# CCG2 register map
File version: 1.0
CPU: CM0 r1p0, little endian, no MPU, no FPU, 2 interrupt priority bits
Registers are 32-bit, read-write, reset 0x0 unless marked. A register's access mark holds for its fields unless they carry their own. Offsets are from the block's base; [hi:lo] are bit positions; lines under a group give offsets from that group; {n}, {i} and the like mark numbered series; 'fields as' and 'values as' point back to an identical list; <NAME> marks a mode.

## GPIO
Base 0x40040000
0x00 PRT0 group
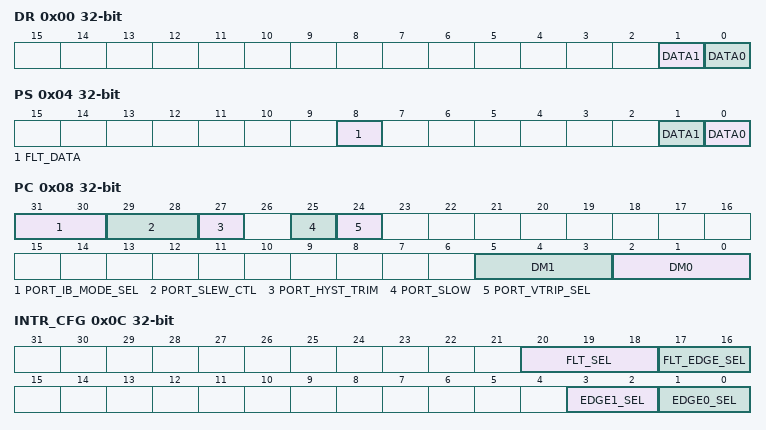
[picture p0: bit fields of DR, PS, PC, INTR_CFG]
  0x00 DR — Port output data register Used to read and write the output data for the IO pads in the port. A DR register write changes the output data to the written value. A DR register read reflects the output data (and not the current state of the input data for the IO pads). Using this DR register, Read-Modify-Write sequences are safely performed on a port with some IO pads configured as inputs.
    [1] DATA1 — IO pad 1 output data.
    [0] DATA0 — IO pad 0 output data.
  0x04 PS — Port IO pad state register Used to read. Writes to this register have no effect. If the drive mode for the pin is set to high Z Analog, the state will read 0 independent of the voltage on the pin.
    [8] FLT_DATA ro — Reads of this register return the logical state of the filtered pin.
    [1] DATA1 ro — IO pad 1 state.
    [0] DATA0 ro — IO pad 0 state: 1: Logic high, if the pin voltage is above the input buffer threshold, logic high. 0: Logic low, if the pin voltage is below that threshold, logic low. If the drive mode for the pin is set to high Z Analog, the pin state will read 0 independent of the voltage on the pin.
  0x08 PC — Port configuration register Configures the output drive and input buffer state for each pin, and the slew rate and input threshold selection for the whole port. One register is provided per port.
    [31:30] PORT_IB_MODE_SEL — This field selects the input buffer reference. The size (1 or 2 bits) and functionality is dependent on the IO cell. For GPIOv2 IO cells, bit PORT_IB_MODE_SEL[1] is not used (GPIOv2 IO cell replaces GPIO IO cell): "0"/"2": CMOS input buffer (PORT_VTRIP_SEL is '0'), LVTTL input buffer (PORT_VTRIP_SEL is '1') "1"/"3": vcchib. For GPIO_OVTv2 and SIOv2 IO cells: "0": CMOS input buffer (PORT_VTRIP_SEL is '0'), LVTTL input buffer (PORT_VTRIP_SEL is '1') "1": vcchib. "2": OVT. "3": Reference (possibly from reference generator cell). For SIO IO cell, this field is present but not used as the SIO IO cell does not provide input buffer mode select functionality (SIOv2 IO cell will replace SIO IO cell, as soon as it is available).
    [29:28] PORT_SLEW_CTL — Slew control. Only used in the O_Z drive mode (mode 4: strong pull down, open drain): This field is intended for I2C functionality. See BROS 001-70428 for more details.
    [27] PORT_HYST_TRIM — This field is used to improve the hysteresis (to 10% of vddio) of the selectable trip point input buffer. The voltage reference comes from the VREFGEN block and is only available when using the VREFGEN block: '0': <= 2.2 V input signaling Voltage. '1': > 2.2 V input signaling Voltage.
    [25] PORT_SLOW — This field controls the output edge rate of all pins on the port: '0': fast. '1': slow.
    [24] PORT_VTRIP_SEL — The GPIO cells include a VTRIP_SEL signal to alter the input buffer voltage. Note: this bit is ignored for SIO ports, the VTRIP_SEL settings in the SIO register are used instead (a separate VTRIP_SEL is provided for each pin pair). 0: input buffer functions as a CMOS input buffer. 1: input buffer functions as a LVTTL input buffer.
    [5:3] DM1 — The GPIO drive mode for IO pad 1.
    [2:0] DM0 — The GPIO drive mode for IO pad 0. Note: when initializing IO's that are connected to a live bus (such as I2C), make sure the HSIOM is properly configured (HSIOM_PRT_SELx) before turning the IO on here to avoid producing glitches on the bus.
      0=OFF; 1=INPUT; 2=0_PU; 3=PD_1; 4=0_Z; 5=Z_1; 6=0_1; 7=PD_PU
  0x0C INTR_CFG — Port interrupt configuration register This register configures the IRQ configuration for all pins in a port, with the IRQ type being individually pin-configurable.
    [20:18] FLT_SEL — Selects which pin is routed through the 50ns glitch filter to provide a glitch-safe interrupt.
    [17:16] FLT_EDGE_SEL — Same for the glitch filtered pin (selected by FLT_SELECT).
      0=DISABLE; 1=RISING; 2=FALLING; 3=BOTH
    [3:2] EDGE1_SEL — Sets which edge will trigger an IRQ for IO pad 1.
    [1:0] EDGE0_SEL — Sets which edge will trigger an IRQ for IO pad 0.
      0=DISABLE; 1=RISING; 2=FALLING; 3=BOTH
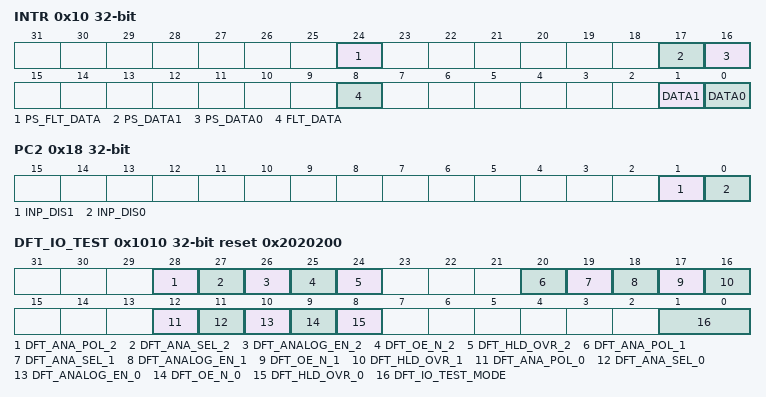
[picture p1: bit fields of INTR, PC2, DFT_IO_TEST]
  0x10 INTR — Port interrupt status register An interrupt cause is cleared (set to '0') by writing a '1' to the corresponding bit field. It is not recommended to write 0xff to clear all interrupt causes, as a new interrupt cause may have occurred between reading the register and clearing. Note that the interrupt cause fields and the associated interrupt provide Hibernate functionality (interrupt causes can be set to '1' and the interrupt can be activated in Hibernate power mode). The PS_DATA fields reflect the logical IO pad states of the port (also found in the PS register).
    [24] PS_FLT_DATA ro — This is a duplicate of the contents of the PS register, provided here to allow reading of both pin state and interrupt state of the port in a single read operation.
    [17] PS_DATA1 ro
    [16] PS_DATA0 ro — `
    [8] FLT_DATA write-1-clears — Deglitched interrupt pending (selected by FLT_SELECT).
    [1] DATA1 write-1-clears — Interrupt pending on IO pad 1. Firmware writes 1 to clear the interrupt.
    [0] DATA0 write-1-clears — Interrupt pending on IO pad 0. Firmware writes 1 to clear the interrupt.
  0x18 PC2 — Port configuration register 2 Configures the input disable for each pin.
    [1] INP_DIS1 — Disables the input buffer for IO pad 1.
    [0] INP_DIS0 — Disables the input buffer for IO pad 0 independent of the port control drive mode (PC.DM). This bit should be set when analog signals are present on the pin and PC.DM != 0 is required to use the output driver.
  0x40 DR_SET — Port output data set register Used to set output data of specific IO pads in the corresponding port to '1', without affecting the output data of the other IO pads in the port. A DR_SET register read returns the same value as a DR register read.
    [7:0] DATA — IO pad i: '0': Output state DR.DATA[i] not affected. '1': Output state DR.DATA[i] set to '1'.
  0x44 DR_CLR — Port output data clear register Used to clear output data of specific IO pads in the corresponding port to '0', without affecting the output data of the other IO pads in the port. A DR_CLR register read returns the same value as a DR register read.
    [7:0] DATA — IO pad i: '0': Output state DR.DATA[i] not affected. '1': Output state DR.DATA[i] set to '0'.
  0x48 DR_INV — Port output data invert register Used to invert output data of specific IO pads in the corresponding port, without affecting the output data of the other IO pads in the port. A DR_INV register read returns the same value as a DR register read.
    [7:0] DATA — IO pad i: '0': Output state DR.DATA[i] not affected. '1': Output state DR.DATA[i] inverted ('0' => '1', '1' => '0').
0x100 PRT1 group
  0x00 DR — Port output data register Used to read and write the output data for the IO pads in the port. A DR register write changes the output data to the written value. A DR register read reflects the output data (and not the current state of the input data for the IO pads). Using this DR register, Read-Modify-Write sequences are safely performed on a port with some IO pads configured as inputs.
    [n] DATA{n} (n=2..7)
    [1] DATA1 — IO pad 1 output data.
    [0] DATA0 — IO pad 0 output data.
  0x04 PS — Port IO pad state register Used to read. Writes to this register have no effect. If the drive mode for the pin is set to high Z Analog, the state will read 0 independent of the voltage on the pin.
    [8] FLT_DATA ro — Reads of this register return the logical state of the filtered pin.
    [n] DATA{n} ro (n=2..7)
    [1] DATA1 ro — IO pad 1 state.
    [0] DATA0 ro — IO pad 0 state: 1: Logic high, if the pin voltage is above the input buffer threshold, logic high. 0: Logic low, if the pin voltage is below that threshold, logic low. If the drive mode for the pin is set to high Z Analog, the pin state will read 0 independent of the voltage on the pin.
  0x08 PC — Port configuration register Configures the output drive and input buffer state for each pin, and the slew rate and input threshold selection for the whole port. One register is provided per port.
    [31:30] PORT_IB_MODE_SEL — This field selects the input buffer reference. The size (1 or 2 bits) and functionality is dependent on the IO cell. For GPIOv2 IO cells, bit PORT_IB_MODE_SEL[1] is not used (GPIOv2 IO cell replaces GPIO IO cell): "0"/"2": CMOS input buffer (PORT_VTRIP_SEL is '0'), LVTTL input buffer (PORT_VTRIP_SEL is '1') "1"/"3": vcchib. For GPIO_OVTv2 and SIOv2 IO cells: "0": CMOS input buffer (PORT_VTRIP_SEL is '0'), LVTTL input buffer (PORT_VTRIP_SEL is '1') "1": vcchib. "2": OVT. "3": Reference (possibly from reference generator cell). For SIO IO cell, this field is present but not used as the SIO IO cell does not provide input buffer mode select functionality (SIOv2 IO cell will replace SIO IO cell, as soon as it is available).
    [25] PORT_SLOW — This field controls the output edge rate of all pins on the port: '0': fast. '1': slow.
    [24] PORT_VTRIP_SEL — The GPIO cells include a VTRIP_SEL signal to alter the input buffer voltage. Note: this bit is ignored for SIO ports, the VTRIP_SEL settings in the SIO register are used instead (a separate VTRIP_SEL is provided for each pin pair). 0: input buffer functions as a CMOS input buffer. 1: input buffer functions as a LVTTL input buffer.
    [3n+2:3n] DM{n} (n=2..7)
    [5:3] DM1 — The GPIO drive mode for IO pad 1.
    [2:0] DM0 — The GPIO drive mode for IO pad 0. Note: when initializing IO's that are connected to a live bus (such as I2C), make sure the HSIOM is properly configured (HSIOM_PRT_SELx) before turning the IO on here to avoid producing glitches on the bus.
      0=OFF; 1=INPUT; 2=0_PU; 3=PD_1; 4=0_Z; 5=Z_1; 6=0_1; 7=PD_PU
  0x0C INTR_CFG — Port interrupt configuration register This register configures the IRQ configuration for all pins in a port, with the IRQ type being individually pin-configurable.
    [20:18] FLT_SEL — Selects which pin is routed through the 50ns glitch filter to provide a glitch-safe interrupt.
    [17:16] FLT_EDGE_SEL — Same for the glitch filtered pin (selected by FLT_SELECT).
      0=DISABLE; 1=RISING; 2=FALLING; 3=BOTH
    [2n+1:2n] EDGE{n}_SEL (n=2..7)
    [3:2] EDGE1_SEL — Sets which edge will trigger an IRQ for IO pad 1.
    [1:0] EDGE0_SEL — Sets which edge will trigger an IRQ for IO pad 0.
      0=DISABLE; 1=RISING; 2=FALLING; 3=BOTH
  0x10 INTR — Port interrupt status register An interrupt cause is cleared (set to '0') by writing a '1' to the corresponding bit field. It is not recommended to write 0xff to clear all interrupt causes, as a new interrupt cause may have occurred between reading the register and clearing. Note that the interrupt cause fields and the associated interrupt provide Hibernate functionality (interrupt causes can be set to '1' and the interrupt can be activated in Hibernate power mode). The PS_DATA fields reflect the logical IO pad states of the port (also found in the PS register).
    [24] PS_FLT_DATA ro — This is a duplicate of the contents of the PS register, provided here to allow reading of both pin state and interrupt state of the port in a single read operation.
    [n+16] PS_DATA{n} ro (n=1..7)
    [16] PS_DATA0 ro — `
    [8] FLT_DATA write-1-clears — Deglitched interrupt pending (selected by FLT_SELECT).
    [n] DATA{n} write-1-clears (n=2..7)
    [1] DATA1 write-1-clears — Interrupt pending on IO pad 1. Firmware writes 1 to clear the interrupt.
    [0] DATA0 write-1-clears — Interrupt pending on IO pad 0. Firmware writes 1 to clear the interrupt.
  0x18 PC2 — Port configuration register 2 Configures the input disable for each pin.
    [n] INP_DIS{n} (n=2..7)
    [1] INP_DIS1 — Disables the input buffer for IO pad 1.
    [0] INP_DIS0 — Disables the input buffer for IO pad 0 independent of the port control drive mode (PC.DM). This bit should be set when analog signals are present on the pin and PC.DM != 0 is required to use the output driver.
  0x40 DR_SET — Port output data set register Used to set output data of specific IO pads in the corresponding port to '1', without affecting the output data of the other IO pads in the port. A DR_SET register read returns the same value as a DR register read.
    fields as PRT0.DR_SET
  0x44 DR_CLR — Port output data clear register Used to clear output data of specific IO pads in the corresponding port to '0', without affecting the output data of the other IO pads in the port. A DR_CLR register read returns the same value as a DR register read.
    fields as PRT0.DR_CLR
  0x48 DR_INV — Port output data invert register Used to invert output data of specific IO pads in the corresponding port, without affecting the output data of the other IO pads in the port. A DR_INV register read returns the same value as a DR register read.
    fields as PRT0.DR_INV
0x200 PRT2 group
  0x00 DR — Port output data register Used to read and write the output data for the IO pads in the port. A DR register write changes the output data to the written value. A DR register read reflects the output data (and not the current state of the input data for the IO pads). Using this DR register, Read-Modify-Write sequences are safely performed on a port with some IO pads configured as inputs.
    [3] DATA3
    [2] DATA2
    [1] DATA1 — IO pad 1 output data.
    [0] DATA0 — IO pad 0 output data.
  0x04 PS — Port IO pad state register Used to read. Writes to this register have no effect. If the drive mode for the pin is set to high Z Analog, the state will read 0 independent of the voltage on the pin.
    [8] FLT_DATA ro — Reads of this register return the logical state of the filtered pin.
    [3] DATA3 ro
    [2] DATA2 ro
    [1] DATA1 ro — IO pad 1 state.
    [0] DATA0 ro — IO pad 0 state: 1: Logic high, if the pin voltage is above the input buffer threshold, logic high. 0: Logic low, if the pin voltage is below that threshold, logic low. If the drive mode for the pin is set to high Z Analog, the pin state will read 0 independent of the voltage on the pin.
  0x08 PC — Port configuration register Configures the output drive and input buffer state for each pin, and the slew rate and input threshold selection for the whole port. One register is provided per port.
    [31:30] PORT_IB_MODE_SEL — This field selects the input buffer reference. The size (1 or 2 bits) and functionality is dependent on the IO cell. For GPIOv2 IO cells, bit PORT_IB_MODE_SEL[1] is not used (GPIOv2 IO cell replaces GPIO IO cell): "0"/"2": CMOS input buffer (PORT_VTRIP_SEL is '0'), LVTTL input buffer (PORT_VTRIP_SEL is '1') "1"/"3": vcchib. For GPIO_OVTv2 and SIOv2 IO cells: "0": CMOS input buffer (PORT_VTRIP_SEL is '0'), LVTTL input buffer (PORT_VTRIP_SEL is '1') "1": vcchib. "2": OVT. "3": Reference (possibly from reference generator cell). For SIO IO cell, this field is present but not used as the SIO IO cell does not provide input buffer mode select functionality (SIOv2 IO cell will replace SIO IO cell, as soon as it is available).
    [25] PORT_SLOW — This field controls the output edge rate of all pins on the port: '0': fast. '1': slow.
    [24] PORT_VTRIP_SEL — The GPIO cells include a VTRIP_SEL signal to alter the input buffer voltage. Note: this bit is ignored for SIO ports, the VTRIP_SEL settings in the SIO register are used instead (a separate VTRIP_SEL is provided for each pin pair). 0: input buffer functions as a CMOS input buffer. 1: input buffer functions as a LVTTL input buffer.
    [11:9] DM3
    [8:6] DM2
    [5:3] DM1 — The GPIO drive mode for IO pad 1.
    [2:0] DM0 — The GPIO drive mode for IO pad 0. Note: when initializing IO's that are connected to a live bus (such as I2C), make sure the HSIOM is properly configured (HSIOM_PRT_SELx) before turning the IO on here to avoid producing glitches on the bus.
      0=OFF; 1=INPUT; 2=0_PU; 3=PD_1; 4=0_Z; 5=Z_1; 6=0_1; 7=PD_PU
  0x0C INTR_CFG — Port interrupt configuration register This register configures the IRQ configuration for all pins in a port, with the IRQ type being individually pin-configurable.
    [20:18] FLT_SEL — Selects which pin is routed through the 50ns glitch filter to provide a glitch-safe interrupt.
    [17:16] FLT_EDGE_SEL — Same for the glitch filtered pin (selected by FLT_SELECT).
      0=DISABLE; 1=RISING; 2=FALLING; 3=BOTH
    [7:6] EDGE3_SEL
    [5:4] EDGE2_SEL
    [3:2] EDGE1_SEL — Sets which edge will trigger an IRQ for IO pad 1.
    [1:0] EDGE0_SEL — Sets which edge will trigger an IRQ for IO pad 0.
      0=DISABLE; 1=RISING; 2=FALLING; 3=BOTH
  0x10 INTR — Port interrupt status register An interrupt cause is cleared (set to '0') by writing a '1' to the corresponding bit field. It is not recommended to write 0xff to clear all interrupt causes, as a new interrupt cause may have occurred between reading the register and clearing. Note that the interrupt cause fields and the associated interrupt provide Hibernate functionality (interrupt causes can be set to '1' and the interrupt can be activated in Hibernate power mode). The PS_DATA fields reflect the logical IO pad states of the port (also found in the PS register).
    [24] PS_FLT_DATA ro — This is a duplicate of the contents of the PS register, provided here to allow reading of both pin state and interrupt state of the port in a single read operation.
    [19] PS_DATA3 ro
    [18] PS_DATA2 ro
    [17] PS_DATA1 ro
    [16] PS_DATA0 ro — `
    [8] FLT_DATA write-1-clears — Deglitched interrupt pending (selected by FLT_SELECT).
    [3] DATA3 write-1-clears
    [2] DATA2 write-1-clears
    [1] DATA1 write-1-clears — Interrupt pending on IO pad 1. Firmware writes 1 to clear the interrupt.
    [0] DATA0 write-1-clears — Interrupt pending on IO pad 0. Firmware writes 1 to clear the interrupt.
  0x18 PC2 — Port configuration register 2 Configures the input disable for each pin.
    [3] INP_DIS3
    [2] INP_DIS2
    [1] INP_DIS1 — Disables the input buffer for IO pad 1.
    [0] INP_DIS0 — Disables the input buffer for IO pad 0 independent of the port control drive mode (PC.DM). This bit should be set when analog signals are present on the pin and PC.DM != 0 is required to use the output driver.
  0x40 DR_SET — Port output data set register Used to set output data of specific IO pads in the corresponding port to '1', without affecting the output data of the other IO pads in the port. A DR_SET register read returns the same value as a DR register read.
    fields as PRT0.DR_SET
  0x44 DR_CLR — Port output data clear register Used to clear output data of specific IO pads in the corresponding port to '0', without affecting the output data of the other IO pads in the port. A DR_CLR register read returns the same value as a DR register read.
    fields as PRT0.DR_CLR
  0x48 DR_INV — Port output data invert register Used to invert output data of specific IO pads in the corresponding port, without affecting the output data of the other IO pads in the port. A DR_INV register read returns the same value as a DR register read.
    fields as PRT0.DR_INV
0x1000 INTR_CAUSE — Interrupt port cause register
  [2:0] PORT_INT ro — Each IO port has an associated bit field in this register. The bit field reflects the IO port's interrupt line (bit field i reflects "gpio_interrupts[i]" for IO port i). The register is used when the system uses a shared/combined interrupt line "gpio_interrupt". The SW ISR reads the register to deternine which IO port(s) is responsible for the shared/combined interrupt line "gpio_interrupt". Once, the IO port(s) is determined, the IO port's INTR register is read to determine the IO pad(s) in the IO port that caused the interrupt.
0x1010 DFT_IO_TEST reset 0x2020200 — IO SELF TEST control register for DfT purposes only This register is used to significantly reduce the test time for IO cells. It also avoids the need to develop a large amount of chip specific functional test vectors. With ATPG it is not possible to get full stuck-at fault coverage for some IO cell inputs (�hld_ovr, oe_n, analog_en, analog_sel, analog_pol�). This register gives direct controlabilty on those inputs of all IO cells by bypassing the functional paths. That allows generic (not chip specific) ROOS code (also SWD IO cells are included) to get DfT fault-coverage for these signals. This register is used in conjunction with the GPIO.PC.dm[2:0], GPIO.DR.out and SRSS.CORE.PWR_STOP.FREEZE for control and results are observed through GPIO.PS.data. Only one IO cell on the whole chip gets IO_TEST_0 and only one gets IO_TEST_1 and default values of IO_TEST_0 is '0' and IO_TEST_1 is '1'. Also only one IO cell on the whole chip gets asssigned ADFT-0 and only one gets asssigned ADFT-1. All four IO_TEST_0/1 and ADFT-0/1 pins are assigned in the product pin spreadsheet.
  [28] DFT_ANA_POL_2 — �analog_pol� DfT control for IO cells depending on DFT_IO_TEST_MODE as given below. TEST_ADFT: Connects to �analog_pol� of all IO cells other than ADFT-0/1. TEST_ANA: Connects to �analog_pol� of all IO cells other than IO_TEST_0/1. TEST_GEN: Connects to �analog_pol� of all IO cells.
  [27] DFT_ANA_SEL_2 — �analog_sel� DfT control for IO cells depending on DFT_IO_TEST_MODE as given below. TEST_ADFT: Connects to �analog_sel� of all IO cells other than ADFT-0/1. TEST_ANA: Connects to �analog_sel� of all IO cells other than IO_TEST_0/1. TEST_GEN: Connects to �analog_sel� of all IO cells.
  [26] DFT_ANALOG_EN_2 — �analog_en� DfT control for IO cells depending on DFT_IO_TEST_MODE as given below. TEST_ADFT: Connects to �analog_en� of all IO cells other than ADFT-0/1. TEST_ANA: DFT_ANALOG_EN_2 && DM[0] connects to �analog_en� of all IO cells other than IO_TEST_0/1. TEST_GEN: Connects to �analog_en� of all IO cells
  [25] DFT_OE_N_2 — �oe_n� DfT control for IO cells depending on DFT_IO_TEST_MODE as given below. TEST_ADFT: Connects to �oe_n� of all IO cells other than ADFT-0/1. TEST_ANA: Connects to �oe_n� of all IO cells other than IO_TEST_0/1. TEST_GEN: Connects to �oe_n� of all IO cells
  [24] DFT_HLD_OVR_2 — �hld_ovr� DfT control for IO cells depending on DFT_IO_TEST_MODE as given below. TEST_ADFT: Connects to �hld_ovr� of all IO cells other than ADFT-0/1 . TEST_ANA: Connects to �hld_ovr� of all IO cells other than IO_TEST_0/1. TEST_GEN: Connects to �hld_ovr� of all IO cells.
  [20] DFT_ANA_POL_1 — �analog_pol� DfT control for IO cells depending on DFT_IO_TEST_MODE as given below. TEST_ADFT: Connects to �analog_pol� of the ADFT-1 assigned IO cell. TEST_ANA: Connects to �analog_pol� of the IO_TEST_1 assigned IO cell. TEST_GEN: not used.
  [19] DFT_ANA_SEL_1 — �analog_sel� DfT control for IO cells depending on DFT_IO_TEST_MODE as given below. TEST_ADFT: Connects to �analog_sel� of the ADFT-1 assigned IO cell. TEST_ANA: Connects to �analog_sel� of the IO_TEST_1 assigned IO cell. TEST_GEN: not used.
  [18] DFT_ANALOG_EN_1 — �analog_en� DfT control for IO cells depending on DFT_IO_TEST_MODE as given below. TEST_ADFT: Connects to �analog_en� of the ADFT-1 assigned IO cell. TEST_ANA: Connects to �analog_en� of the IO_TEST_1 assigned IO cell. TEST_GEN: not used.
  [17] DFT_OE_N_1 — �oe_n� DfT control for IO cells depending on DFT_IO_TEST_MODE as given below. TEST_ADFT: Connects to �oe_n� of the ADFT-1 assigned IO cell. TEST_ANA: Connects to �oe_n� of the IO_TEST_1 assigned IO cell. TEST_GEN: not used.
  [16] DFT_HLD_OVR_1 — �hld_ovr� DfT control for IO cells depending on DFT_IO_TEST_MODE as given below. TEST_ADFT: Connects to �hld_ovr� of the ADFT-1 assigned IO cell. TEST_ANA: Connects to �hld_ovr� of the IO_TEST_1 assigned IO cell. TEST_GEN: not used.
  [12] DFT_ANA_POL_0 — �analog_pol� DfT control for IO cells depending on DFT_IO_TEST_MODE as given below. TEST_ADFT: Connects to �analog_pol� of the ADFT-0 assigned IO cell. TEST_ANA: Connects to �analog_pol� of the IO_TEST_0 assigned IO cell. TEST_GEN: not used.
  [11] DFT_ANA_SEL_0 — �analog_sel� DfT control for IO cells depending on DFT_IO_TEST_MODE as given below. TEST_ADFT: Connects to �analog_sel� of the ADFT-0 assigned IO cell. TEST_ANA: Connects to �analog_sel� of the IO_TEST_0 assigned IO cell. TEST_GEN: not used.
  [10] DFT_ANALOG_EN_0 — �analog_en� DfT control for IO cells depending on DFT_IO_TEST_MODE as given below. TEST_ADFT: Connects to �analog_en� of the ADFT-0 assigned IO cell. TEST_ANA: Connects to �analog_en� of the IO_TEST_0 assigned IO cell. TEST_GEN: not used.
  [9] DFT_OE_N_0 — �oe_n� DfT control for IO cells depending on DFT_IO_TEST_MODE as given below. TEST_ADFT: Connects to �oe_n� of the ADFT-0 assigned IO cell. TEST_ANA: Connects to �oe_n� of the IO_TEST_0 assigned IO cell. TEST_GEN: not used.
  [8] DFT_HLD_OVR_0 — �hld_ovr� DfT control for IO cells depending on DFT_IO_TEST_MODE as given below. TEST_ADFT: Connects to �hld_ovr� of the ADFT-0 assigned IO cell. TEST_ANA: Connects to �hld_ovr� of the IO_TEST_0 assigned IO cell. TEST_GEN: not used.
  [1:0] DFT_IO_TEST_MODE — DfT IO SELF TEST mode:
    0=OFF; 1=TEST_ADFT; 2=TEST_ANA; 3=TEST_GEN
